# PY32T020xx register map
Vendor: Puya; Series: PY32L0; File version: 1.0.0
CPU: CM0+ r0p1, little endian, no MPU, no FPU, 4 interrupt priority bits
Registers are 32-bit, read-write, reset 0x0 unless marked. A register's access mark holds for its fields unless they carry their own. Offsets are from the block's base; [hi:lo] are bit positions; {n}, {i} and the like mark numbered series.

## SYSCFG — System configuration controller
Base 0x40010000
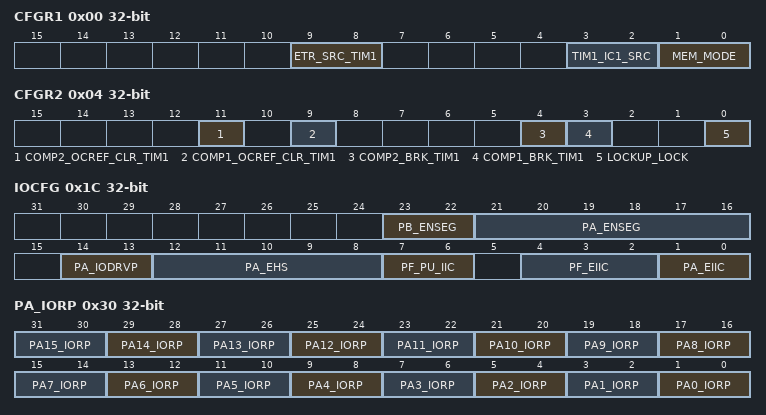
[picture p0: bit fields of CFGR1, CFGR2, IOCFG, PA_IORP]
0x00 CFGR1 — SYSCFG configuration register 1
  [all] fields
    1=0; 2=1
  [9:8] ETR_SRC_TIM1 — Timer1 ETR Input Selection
  [3:2] TIM1_IC1_SRC — Timer1 CH1 Input Selection
  [1:0] MEM_MODE — Storage Area Mapping Selection
0x04 CFGR2 — SYSCFG configuration register 2
  [11] COMP2_OCREF_CLR_TIM1 — COMP2 as TIM1 ocref_clr Enable
  [9] COMP1_OCREF_CLR_TIM1 — COMP1 as TIM1 ocref_clr Enable
  [4] COMP2_BRK_TIM1 — COMP2 as TIM1 Break Enable
  [3] COMP1_BRK_TIM1 — COMP1 as TIM1 Break Enable
  [0] LOCKUP_LOCK — LOCK_UP as TIM1 Break Enable
0x10 PA_ENS
  [15:0] PA_ENS — Pa Noise filter enable
0x14 PB_ENS
  [3:0] PB_ENS — Pb Noise filter enable
0x18 PF_ENS
  [5:0] PF_ENS — Pf Noise filter enable
0x1C IOCFG
  [23:22] PB_ENSEG — Pb Seg Mode enable
    1=0; 2=1
  [21:16] PA_ENSEG — Pa Seg Mode enable
    1=0; 2=1; 4=2; 8=3; 16=4; 32=5
  [14:13] PA_IODRVP — Pa I2C_VCC Output Drive config
    1=0; 2=1
  [12:8] PA_EHS — Pa LED IO Conrtol
    1=0; 2=1; 4=2; 8=3; 16=4
  [7:6] PF_PU_IIC — Pf I2C Pull-up resistor control enable
    1=0; 2=1
  [4:2] PF_EIIC — Pf I2C IO enable
    1=0; 2=1; 4=2
  [1:0] PA_EIIC — Pa I2C IO enable
    1=0; 2=1
0x20 PA_ANA2EN
  [15:0] PA_ANA2EN — Pa Analog Noise filter enable
0x24 PB_ANA2EN
  [3:0] PB_ENS — Pb Analog Noise filter enable
0x28 PF_ANA2EN
  [5:0] PF_ANA2EN — Pf Analog Noise filter enable
0x30 PA_IORP
  [all] fields
    1=0; 2=1
  [2n+1:2n] PA{n}_IORP (n=0..15) — Pa{n} IO pull-up pull-down resistance config
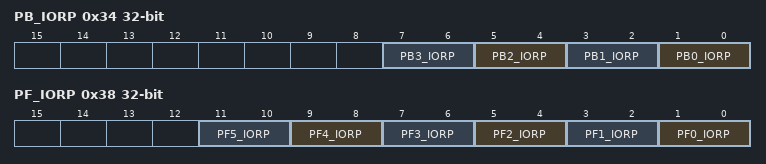
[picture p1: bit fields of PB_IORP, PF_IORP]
0x34 PB_IORP
  [all] fields
    1=0; 2=1
  [2n+1:2n] PB{n}_IORP (n=0..3) — Pb{n} IO pull-up pull-down resistance config
0x38 PF_IORP
  [all] fields
    1=0; 2=1
  [2n+1:2n] PF{n}_IORP (n=0..5) — Pf{n} IO pull-up pull-down resistance config

## TIM1 — Advanced timer
Base 0x40012C00
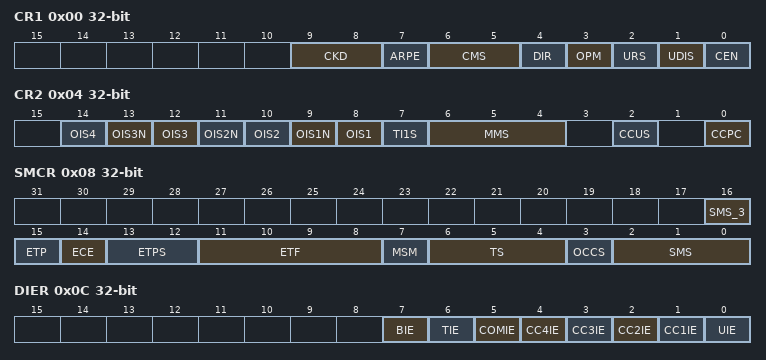
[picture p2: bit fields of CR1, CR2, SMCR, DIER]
0x00 CR1
  [9:8] CKD
    1=0; 2=1
  [7] ARPE
  [6:5] CMS
    1=0; 2=1
  [4] DIR
  [3] OPM
  [2] URS
  [1] UDIS
  [0] CEN
0x04 CR2 (reset mask 0xF8)
  [2n+6] OIS{n} (n=1..4)
  [13] OIS3N
  [11] OIS2N
  [9] OIS1N
  [7] TI1S
  [6:4] MMS
    1=0; 2=1; 4=2
  [2] CCUS
  [0] CCPC
0x08 SMCR (reset mask 0xFFF7)
  [16] SMS_3
  [15] ETP
  [14] ECE
  [13:12] ETPS
    1=0; 2=1
  [11:8] ETF
    1=0; 2=1; 4=2; 8=3
  [7] MSM
  [6:4] TS
    1=0; 2=1; 4=2
  [3] OCCS
  [2:0] SMS
0x0C DIER (reset mask 0x5F5F)
  [7] BIE, [6] TIE, [5] COMIE, [n] CC{n}IE (n=1..4), [0] UIE
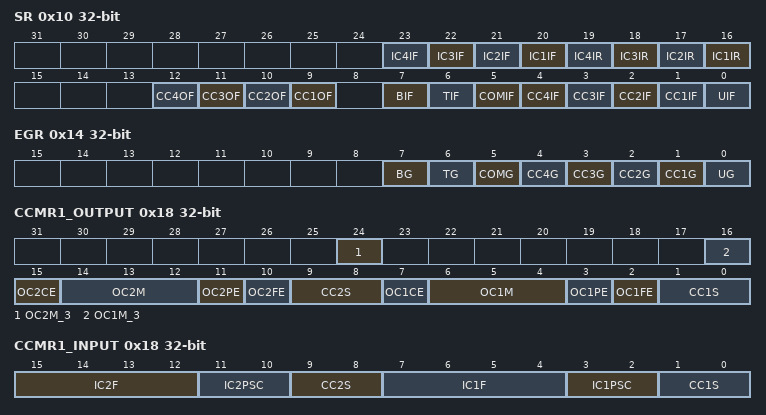
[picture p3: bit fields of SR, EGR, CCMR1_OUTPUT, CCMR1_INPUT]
0x10 SR (reset mask 0x1E5F)
  [n+19] IC{n}IF (n=1..4), [n+15] IC{n}IR (n=1..4), [n+8] CC{n}OF (n=1..4), [7] BIF, [6] TIF, [5] COMIF, [n] CC{n}IF (n=1..4), [0] UIF
0x14 EGR wo (reset mask 0x5F)
  [7] BG
  [6] TG
  [5] COMG
  [4] CC4G
  [3] CC3G
  [2] CC2G
  [1] CC1G — Capture/Compare 1 Generation
  [0] UG
0x18 CCMR1_OUTPUT (reset mask 0xFFFF)
  [24] OC2M_3, [16] OC1M_3, [15] OC2CE, [14:12] OC2M, [11] OC2PE, [10] OC2FE, [9:8] CC2S, [7] OC1CE, [6:4] OC1M, [3] OC1PE, [2] OC1FE, [1:0] CC1S
0x18 CCMR1_INPUT (alternate view of CCMR1_OUTPUT)
  [15:12] IC2F, [11:10] IC2PSC, [9:8] CC2S, [7:4] IC1F, [3:2] IC1PSC, [1:0] CC1S
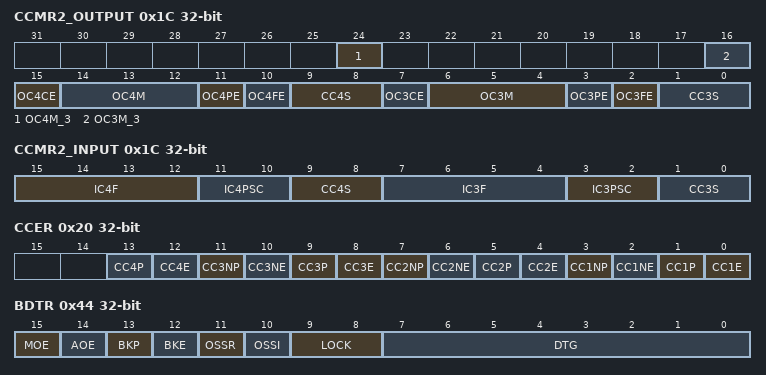
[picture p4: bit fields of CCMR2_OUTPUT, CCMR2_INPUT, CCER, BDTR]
0x1C CCMR2_OUTPUT (reset mask 0xFFFF)
  [24] OC4M_3, [16] OC3M_3, [15] OC4CE, [14:12] OC4M, [11] OC4PE, [10] OC4FE, [9:8] CC4S, [7] OC3CE, [6:4] OC3M, [3] OC3PE, [2] OC3FE, [1:0] CC3S
0x1C CCMR2_INPUT (alternate view of CCMR2_OUTPUT)
  [15:12] IC4F, [11:10] IC4PSC, [9:8] CC4S, [7:4] IC3F, [3:2] IC3PSC, [1:0] CC3S
0x20 CCER (reset mask 0x3333)
  [4n-3] CC{n}P (n=1..4), [4n-4] CC{n}E (n=1..4), [11] CC3NP, [10] CC3NE, [7] CC2NP, [6] CC2NE, [3] CC1NP, [2] CC1NE
0x24 CNT
  [15:0] CNT
0x28 PSC
  [15:0] PSC
0x2C ARR reset 0xFFFF
  [15:0] ARR
0x30 RCR reset 0xFFFF
  [7:0] REP
{0x30+4i} CCR{i} (i=1..4)
  [15:0] CCR{i}
0x44 BDTR
  [15] MOE
  [14] AOE
  [13] BKP
  [12] BKE
  [11] OSSR
  [10] OSSI
  [9:8] LOCK
    1=0; 2=1
  [7:0] DTG
    1=0; 2=1; 4=2; 8=3; 16=4; 32=5; 64=6; 128=7

## TIM14 — General purpose timer
Base 0x40002000
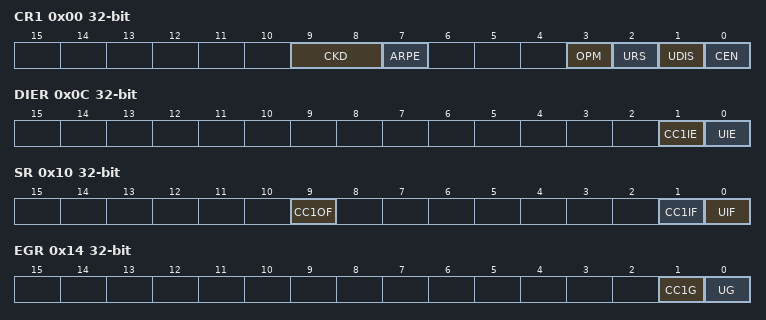
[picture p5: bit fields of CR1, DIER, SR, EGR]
0x00 CR1
  [9:8] CKD
    1=0; 2=1
  [7] ARPE
  [3] OPM
  [2] URS
  [1] UDIS
  [0] CEN
0x0C DIER
  [1] CC1IE, [0] UIE
0x10 SR
  [9] CC1OF, [1] CC1IF, [0] UIF
0x14 EGR wo
  [1] CC1G — Capture/Compare 1 Generation
  [0] UG
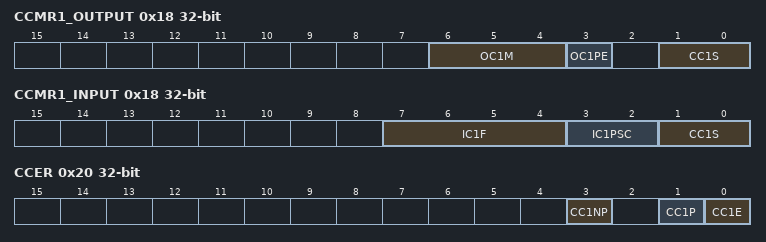
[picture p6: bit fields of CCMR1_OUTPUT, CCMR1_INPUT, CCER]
0x18 CCMR1_OUTPUT
  [6:4] OC1M, [3] OC1PE, [1:0] CC1S
0x18 CCMR1_INPUT (alternate view of CCMR1_OUTPUT)
  [7:4] IC1F, [3:2] IC1PSC, [1:0] CC1S
0x20 CCER (reset mask 0x3333)
  [3] CC1NP, [1] CC1P, [0] CC1E
0x24 CNT
  [15:0] CNT
0x28 PSC
  [15:0] PSC
0x2C ARR reset 0xFFFF
  [15:0] ARR
0x34 CCR1
  [15:0] CCR1
0x50 OR
  [1:0] TI1_RMP
    1=0; 2=1

## UART1 — Universal asynchronous receiver transmitter
Base 0x40004400
Same registers: UART3 0x40013800, UART2 0x40014400
0x00 DR — Data register
  [8:0] DR — Receive/send data register
    1=0; 2=1; 4=2; 8=3; 16=4; 32=5; 64=6; 128=7; 0x100=8
0x04 BRR — Baud rate register
  [15:0] BRR
    1=0; 2=1; 4=2; 8=3; 16=4; 32=5; 64=6; 128=7; 0x100=8; 0x200=9; 0x400=10; 0x800=11; 0x1000=12; 0x2000=13; 0x4000=14; 0x8000=15
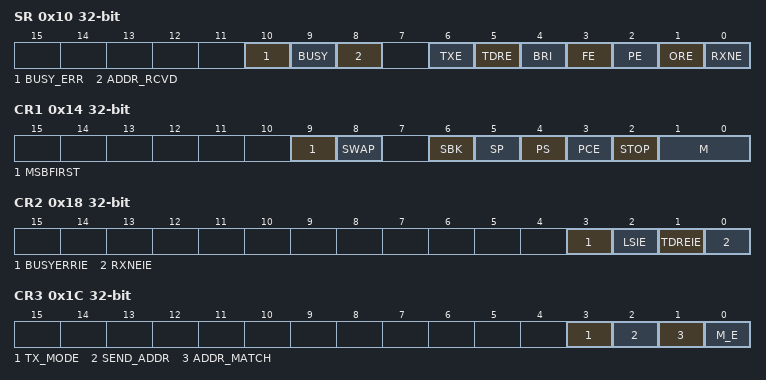
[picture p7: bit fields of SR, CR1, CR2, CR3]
0x10 SR — Status register
  [10] BUSY_ERR — Busy Detect Error
  [9] BUSY ro — UART Busy
  [8] ADDR_RCVD — Address Received Bit
  [6] TXE ro — Transmitter Empty bit
  [5] TDRE ro — Transmit Holding Register Empty bit
  [4] BRI — Break Interrupt bit
  [3] FE — Framing Error bit
  [2] PE — Parity Error bit
  [1] ORE — Overrun error bit
  [0] RXNE ro — Receive register not empty
0x14 CR1 — Control register 1
  [9] MSBFIRST — MSB first mode
  [8] SWAP — TX/RX pin swap
  [6] SBK — Send Break
  [5] SP — Stick Parity
  [4] PS — Even Parity Select
  [3] PCE — Parity Enable
  [2] STOP — Number of stop bits
  [1:0] M — Data Length Select
    3=Char8Bits (8 data bits per character)
0x18 CR2 — Control register 2
  [3] BUSYERRIE — Enable Busyerr state interruption
  [2] LSIE — Enable Receiver Line Status Interrupt
  [1] TDREIE — Enable Transmit Holding Register Empty Interrupt
  [0] RXNEIE — Enable Received Data Available Interrupt
0x1C CR3 — Control register 3
  [3] TX_MODE — Transmit mode control bit
  [2] SEND_ADDR — Send address control bit
  [1] ADDR_MATCH — Address Match Mode
  [0] M_E — Extension for DLS
0x20 RAR
  [7:0] RAR — Receive address matching register
    1=0; 2=1; 4=2; 8=3; 16=4; 32=5; 64=6; 128=7
0x24 TAR
  [7:0] TAR — Transmit address matching register
    1=0; 2=1; 4=2; 8=3; 16=4; 32=5; 64=6; 128=7
